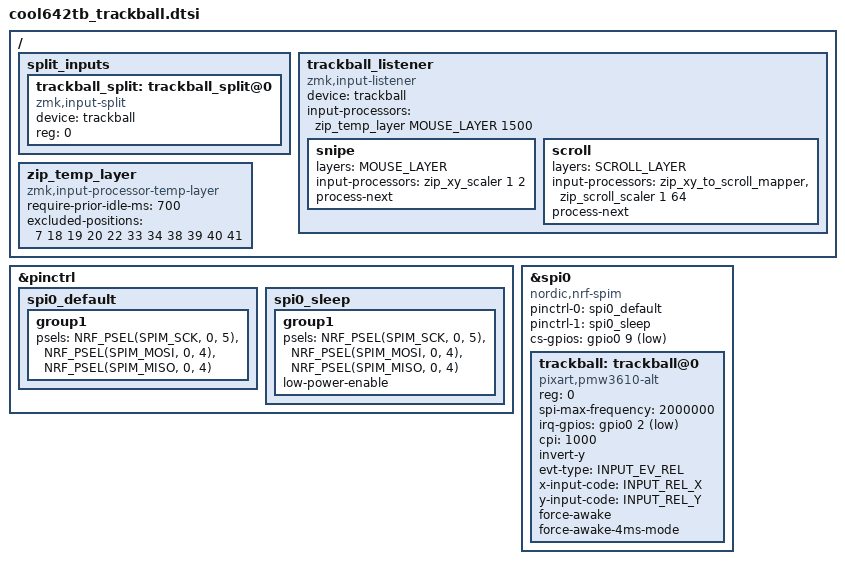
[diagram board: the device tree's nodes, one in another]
#include <zephyr/dt-bindings/input/input-event-codes.h>
#include <input/processors.dtsi>
#include <dt-bindings/zmk/input_transform.h>

#define MOUSE_LAYER 4
#define SCROLL_LAYER 5

&pinctrl {
    spi0_default: spi0_default {
        group1 {
            psels = <NRF_PSEL(SPIM_SCK, 0, 5)>,
                <NRF_PSEL(SPIM_MOSI, 0, 4)>,
                <NRF_PSEL(SPIM_MISO, 0, 4)>;
        };
    };

    spi0_sleep: spi0_sleep {
        group1 {
            psels = <NRF_PSEL(SPIM_SCK, 0, 5)>,
                <NRF_PSEL(SPIM_MOSI, 0, 4)>,
                <NRF_PSEL(SPIM_MISO, 0, 4)>;
            low-power-enable;
        };
    };
};

&spi0 {
    status = "okay";
    compatible = "nordic,nrf-spim";
    pinctrl-0 = <&spi0_default>;
    pinctrl-1 = <&spi0_sleep>;
    pinctrl-names = "default", "sleep";
    cs-gpios = <&gpio0 9 GPIO_ACTIVE_LOW>;

    trackball: trackball@0 {
        status = "okay";
        compatible = "pixart,pmw3610-alt";
        //compatible = "pixart,pmw3610";
        reg = <0>;
        spi-max-frequency = <2000000>;
        //spi-max-frequency = <1000000>;
        irq-gpios = <&gpio0 2 (GPIO_ACTIVE_LOW | GPIO_PULL_UP)>;
        //motion-gpios = <&gpio0 2 (GPIO_ACTIVE_LOW | GPIO_PULL_UP)>;
        cpi = <1000>;
        //res-cpi = <1000>;
        //swap-xy;
        //invert-x;
        invert-y;
        evt-type = <INPUT_EV_REL>;
        x-input-code = <INPUT_REL_X>;
        y-input-code = <INPUT_REL_Y>;
        //invert-x;
        //zephyr,axis-x = <INPUT_REL_Y>;
        //zephyr,axis-y = <INPUT_REL_X>;
        //smart-mode;
        force-awake;
        force-awake-4ms-mode;
    };
};

/ {
    split_inputs {
        #address-cells = <1>;
        #size-cells = <0>;

        trackball_split: trackball_split@0 {
            device = <&trackball>;
            compatible = "zmk,input-split";
            reg = <0>;
        };
    };

    trackball_listener: trackball_listener {
        compatible = "zmk,input-listener";
        status = "okay";
        device = <&trackball>;

        snipe {
        layers = <MOUSE_LAYER>;
        input-processors = <&zip_xy_scaler 1 2>;
        process-next;
        };

        scroll {
        layers = <SCROLL_LAYER>;
        input-processors = <&zip_xy_to_scroll_mapper>, <&zip_scroll_scaler 1 64>;
        process-next;
        };

        input-processors = <&zip_temp_layer MOUSE_LAYER 1500>;

    };

    zip_temp_layer: zip_temp_layer {
        compatible = "zmk,input-processor-temp-layer";
        #input-processor-cells = <2>;
        require-prior-idle-ms = <700>;
        excluded-positions = <
            7 // I
            18  // J
            19 // K
            20 // L
            22 // LEFT_SHIFT
            33 // RIGHT_SHIFT
            34 // LEFT_CTRL
            38 // L SPACE L2
            39 // L SPACE L1
            40 // R SPACE L1
            41 // R SPACE L2
        >; 
    };

};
